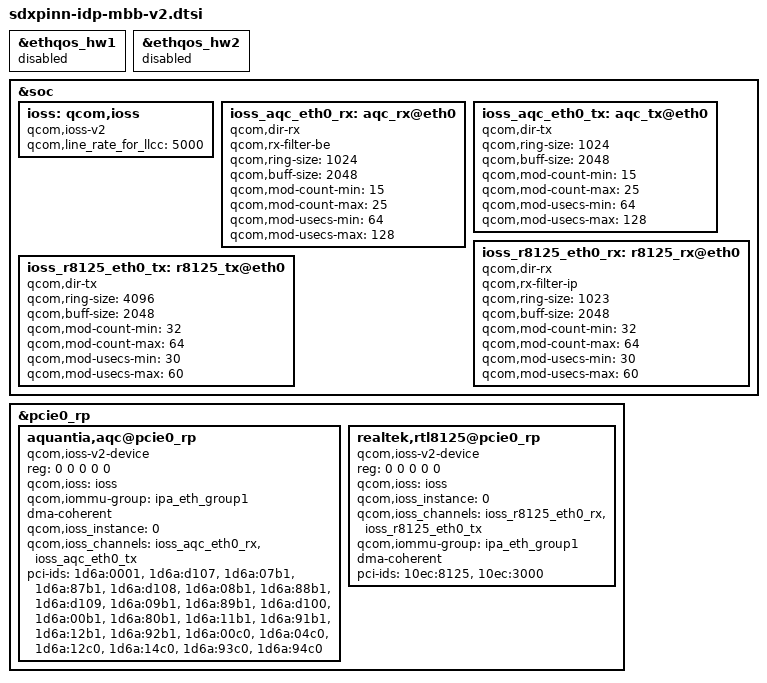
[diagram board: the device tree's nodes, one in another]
#include "sdxpinn-idp-mbb.dtsi"

&ethqos_hw1 {
	status = "disabled";
};

&ethqos_hw2 {
	status = "disabled";
};

&soc {
	ioss: qcom,ioss {
		compatible = "qcom,ioss-v2";
		qcom,line_rate_for_llcc = <5000>;
	};

	ioss_aqc_eth0_rx: aqc_rx@eth0 {
		qcom,dir-rx;
		qcom,rx-filter-be;

		qcom,ring-size = <1024>;
		qcom,buff-size = <2048>;

		qcom,mod-count-min = <15>;
		qcom,mod-count-max = <25>;
		qcom,mod-usecs-min = <64>;
		qcom,mod-usecs-max = <128>;
	};

	ioss_aqc_eth0_tx: aqc_tx@eth0 {
		qcom,dir-tx;
		qcom,ring-size = <1024>;
		qcom,buff-size = <2048>;

		qcom,mod-count-min = <15>;
		qcom,mod-count-max = <25>;
		qcom,mod-usecs-min = <64>;
		qcom,mod-usecs-max = <128>;
	};

	ioss_r8125_eth0_rx: r8125_rx@eth0 {
		qcom,dir-rx;

		qcom,rx-filter-ip;

		qcom,ring-size = <1023>;
		qcom,buff-size = <2048>;

		qcom,mod-count-min = <32>;
		qcom,mod-count-max = <64>;
		qcom,mod-usecs-min = <30>;
		qcom,mod-usecs-max = <60>;
	};

	ioss_r8125_eth0_tx: r8125_tx@eth0 {
		qcom,dir-tx;

		qcom,ring-size = <4096>;
		qcom,buff-size = <2048>;

		qcom,mod-count-min = <32>;
		qcom,mod-count-max = <64>;
		qcom,mod-usecs-min = <30>;
		qcom,mod-usecs-max = <60>;
	};
};

&pcie0_rp {
	aquantia,aqc@pcie0_rp {
		reg = <0 0 0 0 0>;

		compatible = "qcom,ioss-v2-device";
		qcom,ioss = <&ioss>;
		/* ipa shares this group with aqc */
		qcom,iommu-group = <&ipa_eth_group1>;
		dma-coherent;
		qcom,ioss_instance = <0>;
		qcom,ioss_channels =
			<&ioss_aqc_eth0_rx>,
			<&ioss_aqc_eth0_tx>;

		pci-ids =
			"1d6a:0001",
			"1d6a:d107",
			"1d6a:07b1",
			"1d6a:87b1",
			"1d6a:d108",
			"1d6a:08b1",
			"1d6a:88b1",
			"1d6a:d109",
			"1d6a:09b1",
			"1d6a:89b1",
			"1d6a:d100",
			"1d6a:00b1",
			"1d6a:80b1",
			"1d6a:11b1",
			"1d6a:91b1",
			"1d6a:12b1",
			"1d6a:92b1",
			"1d6a:00c0",
			"1d6a:04c0",
			"1d6a:12c0",
			"1d6a:14c0",
			"1d6a:93c0",
			"1d6a:94c0";

	};

	realtek,rtl8125@pcie0_rp {
		compatible = "qcom,ioss-v2-device";

		reg = <0 0 0 0 0>;
		qcom,ioss = <&ioss>;
		qcom,ioss_instance = <0>;
		qcom,ioss_channels =
			<&ioss_r8125_eth0_rx>,
			<&ioss_r8125_eth0_tx>;

		/* ipa shares this group with rtl */
		qcom,iommu-group = <&ipa_eth_group1>;
		dma-coherent;

		pci-ids =
			"10ec:8125",
			"10ec:3000";
	};
};
